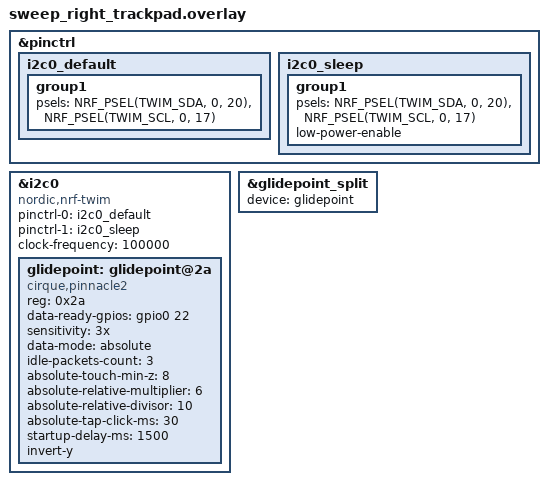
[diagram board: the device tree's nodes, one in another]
&pinctrl {
	i2c0_default: i2c0_default {
		group1 {
			psels = <NRF_PSEL(TWIM_SDA, 0, 20)>,
				<NRF_PSEL(TWIM_SCL, 0, 17)>;
		};
	};

	i2c0_sleep: i2c0_sleep {
		group1 {
			psels = <NRF_PSEL(TWIM_SDA, 0, 20)>,
				<NRF_PSEL(TWIM_SCL, 0, 17)>;
			low-power-enable;
		};
	};
};

&i2c0 {
	compatible = "nordic,nrf-twim";
	status = "okay";

	pinctrl-0 = <&i2c0_default>;
	pinctrl-1 = <&i2c0_sleep>;
	pinctrl-names = "default", "sleep";

	clock-frequency = <100000>;

	glidepoint: glidepoint@2a {
		compatible = "cirque,pinnacle2";
		reg = <0x2a>;
		status = "okay";
		data-ready-gpios = <&gpio0 22 GPIO_ACTIVE_HIGH>;
		sensitivity = "3x";
		data-mode = "absolute";
		idle-packets-count = <3>;
		absolute-touch-min-z = <8>;
		absolute-relative-multiplier = <6>;
		absolute-relative-divisor = <10>;
		absolute-tap-click-ms = <30>;
		startup-delay-ms = <1500>;
		invert-y;
	};
};

&glidepoint_split {
	status = "okay";
	device = <&glidepoint>;
};
